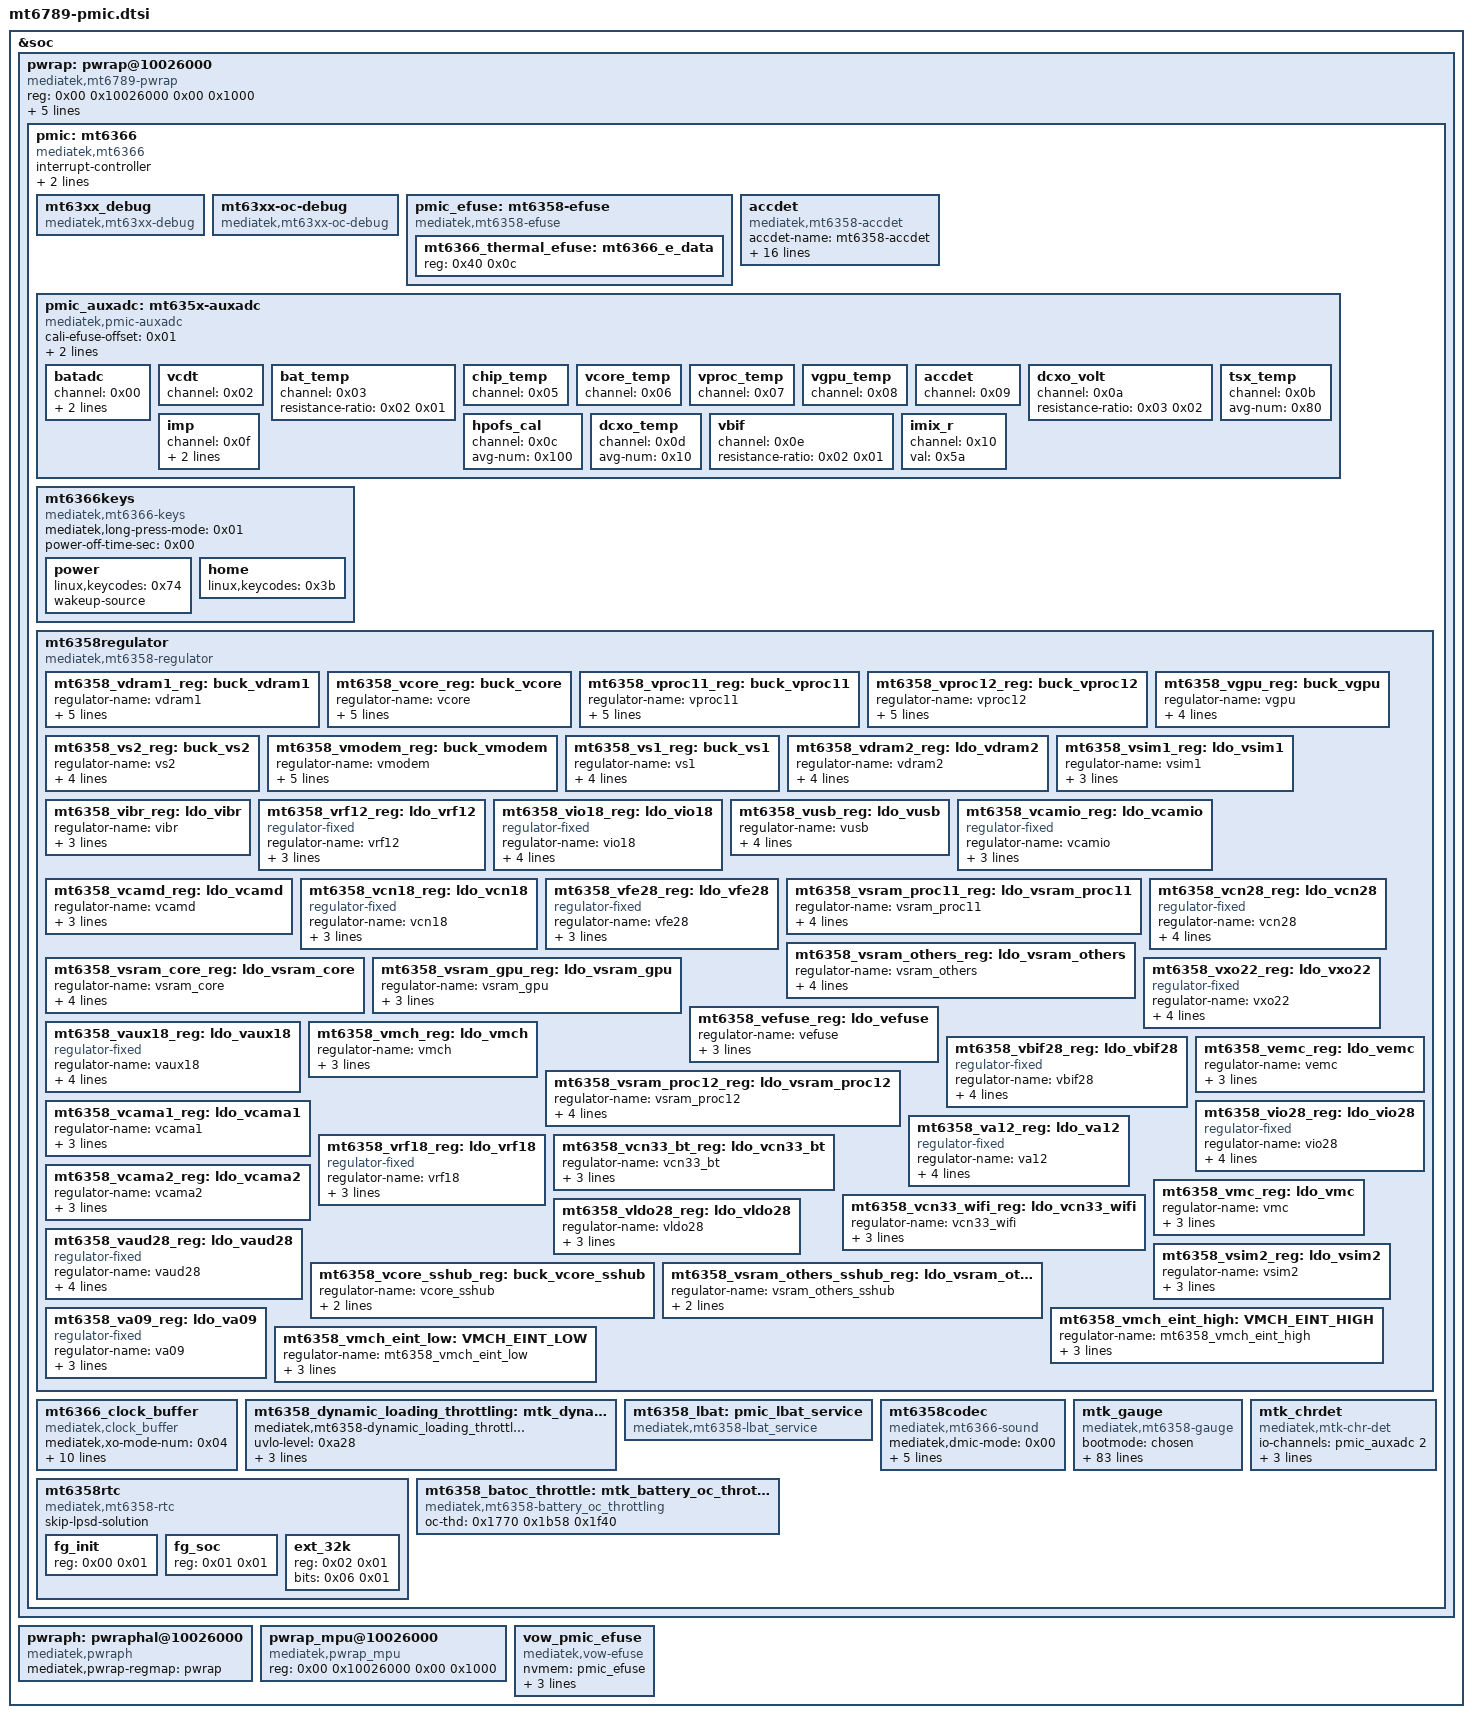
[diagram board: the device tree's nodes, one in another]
// SPDX-License-Identifier: (GPL-2.0 OR MIT)
/* MT6789 pmic blocks -- split out of the SoC node, one subsystem per file. */

&soc {
	pwrap: pwrap@10026000 {
		compatible = "mediatek,mt6789-pwrap";
		reg = <0x00 0x10026000 0x00 0x1000>;
		reg-names = "pwrap";
		interrupts = <GIC_SPI 252 IRQ_TYPE_LEVEL_HIGH 0>;
		clocks = <&infracfg_ao_clk CLK_IFRAO_PMIC_AP &infracfg_ao_clk CLK_IFRAO_PMIC_TMR &topckgen_clk CLK_TOP_PWRAP_ULPOSC_SEL &topckgen_clk CLK_TOP_OSC_D10>;
		clock-names = "spi", "wrap", "ulposc", "ulposc_osc";

		pmic: mt6366 {
			compatible = "mediatek,mt6366";
			interrupt-controller;
			#interrupt-cells = <0x02>;
			interrupt-parent = <&pio>;
			interrupts = <0x89 0x04 0x89 0x00>;

			mt63xx_debug {
				compatible = "mediatek,mt63xx-debug";
			};

			mt63xx-oc-debug {
				compatible = "mediatek,mt63xx-oc-debug";
			};

			pmic_efuse: mt6358-efuse {
				compatible = "mediatek,mt6358-efuse";
				#address-cells = <0x01>;
				#size-cells = <0x01>;

				mt6366_thermal_efuse: mt6366_e_data {
					reg = <0x40 0x0c>;
				};
			};

			accdet: accdet {
				compatible = "mediatek,mt6358-accdet";
				accdet-name = "mt6358-accdet";
				accdet-mic-vol = <0x06>;
				headset-mode-setting = <0x500 0x500 0x01 0x1f0 0x800 0x800 0x20 0x44 0x00 0x00 0x0e 0x00 0x00 0x00 0x00 0x00>;
				accdet-plugout-debounce = <0x01>;
				accdet-mic-mode = <0x01>;
				headset-eint-level-pol = <0x08>;
				headset-three-key-threshold = <0x00 0x50 0xdc 0x190>;
				headset-three-key-threshold-CDD = <0x00 0x79 0xc0 0x258>;
				headset-four-key-threshold = <0x00 0x3a 0x79 0xc0 0x190>;
				io-channels = <&pmic_auxadc 9>;
				io-channel-names = "pmic_accdet";
				nvmem = <&pmic_efuse>;
				nvmem-names = "mt63xx-accdet-efuse";
				mediatek,accdet-pmic = <0x66>;
				status = "okay";
			};

			pmic_auxadc: mt635x-auxadc {
				compatible = "mediatek,pmic-auxadc", "mediatek,mt6358-auxadc";
				#io-channel-cells = <0x01>;
				cali-efuse-offset = <0x01>;
				nvmem = <&pmic_efuse>;
				nvmem-names = "auxadc_efuse_dev";

				batadc {
					channel = <0x00>;
					resistance-ratio = <0x03 0x01>;
					avg-num = <0x80>;
				};

				vcdt {
					channel = <0x02>;
				};

				bat_temp {
					channel = <0x03>;
					resistance-ratio = <0x02 0x01>;
				};

				chip_temp {
					channel = <0x05>;
				};

				vcore_temp {
					channel = <0x06>;
				};

				vproc_temp {
					channel = <0x07>;
				};

				vgpu_temp {
					channel = <0x08>;
				};

				accdet {
					channel = <0x09>;
				};

				dcxo_volt {
					channel = <0x0a>;
					resistance-ratio = <0x03 0x02>;
				};

				tsx_temp {
					channel = <0x0b>;
					avg-num = <0x80>;
				};

				hpofs_cal {
					channel = <0x0c>;
					avg-num = <0x100>;
				};

				dcxo_temp {
					channel = <0x0d>;
					avg-num = <0x10>;
				};

				vbif {
					channel = <0x0e>;
					resistance-ratio = <0x02 0x01>;
				};

				imp {
					channel = <0x0f>;
					resistance-ratio = <0x03 0x01>;
					avg-num = <0x80>;
				};

				imix_r {
					channel = <0x10>;
					val = <0x5a>;
				};
			};

			mt6366keys: mt6366keys {
				compatible = "mediatek,mt6366-keys";
				mediatek,long-press-mode = <0x01>;
				power-off-time-sec = <0x00>;

				power {
					linux,keycodes = <0x74>;
					wakeup-source;
				};

				home {
					linux,keycodes = <0x3b>;
				};
			};

			mt6358regulator: mt6358regulator {
				compatible = "mediatek,mt6358-regulator";

				mt6358_vdram1_reg: buck_vdram1 {
					regulator-name = "vdram1";
					regulator-min-microvolt = <0x7a120>;
					regulator-max-microvolt = <0x1fda4c>;
					regulator-enable-ramp-delay = <0x00>;
					regulator-allowed-modes = <0x00 0x01>;
					regulator-always-on;
				};

				mt6358_vcore_reg: buck_vcore {
					regulator-name = "vcore";
					regulator-min-microvolt = <0x7a120>;
					regulator-max-microvolt = <0x13bdb6>;
					regulator-enable-ramp-delay = <0xc8>;
					regulator-always-on;
					regulator-allowed-modes = <0x00 0x01>;
				};

				mt6358_vproc11_reg: buck_vproc11 {
					regulator-name = "vproc11";
					regulator-min-microvolt = <0x7a120>;
					regulator-max-microvolt = <0x13bdb6>;
					regulator-enable-ramp-delay = <0xc8>;
					regulator-always-on;
					regulator-allowed-modes = <0x00 0x01>;
				};

				mt6358_vproc12_reg: buck_vproc12 {
					regulator-name = "vproc12";
					regulator-min-microvolt = <0x7a120>;
					regulator-max-microvolt = <0x13bdb6>;
					regulator-enable-ramp-delay = <0xc8>;
					regulator-always-on;
					regulator-allowed-modes = <0x00 0x01>;
				};

				mt6358_vgpu_reg: buck_vgpu {
					regulator-name = "vgpu";
					regulator-min-microvolt = <0x7a120>;
					regulator-max-microvolt = <0x13bdb6>;
					regulator-enable-ramp-delay = <0xc8>;
					regulator-allowed-modes = <0x00 0x01>;
				};

				mt6358_vs2_reg: buck_vs2 {
					regulator-name = "vs2";
					regulator-min-microvolt = <0x7a120>;
					regulator-max-microvolt = <0x1fda4c>;
					regulator-enable-ramp-delay = <0x00>;
					regulator-always-on;
				};

				mt6358_vmodem_reg: buck_vmodem {
					regulator-name = "vmodem";
					regulator-min-microvolt = <0x7a120>;
					regulator-max-microvolt = <0x13bdb6>;
					regulator-enable-ramp-delay = <0x384>;
					regulator-always-on;
					regulator-allowed-modes = <0x00 0x01>;
				};

				mt6358_vs1_reg: buck_vs1 {
					regulator-name = "vs1";
					regulator-min-microvolt = <0xf4240>;
					regulator-max-microvolt = <0x277b6c>;
					regulator-enable-ramp-delay = <0x00>;
					regulator-always-on;
				};

				mt6358_vdram2_reg: ldo_vdram2 {
					regulator-name = "vdram2";
					regulator-min-microvolt = <0x927c0>;
					regulator-max-microvolt = <0x1b7740>;
					regulator-enable-ramp-delay = <0xce4>;
					regulator-always-on;
				};

				mt6358_vsim1_reg: ldo_vsim1 {
					regulator-name = "vsim1";
					regulator-min-microvolt = <0x00>;
					regulator-max-microvolt = <0x2f4d60>;
					regulator-enable-ramp-delay = <0x21c>;
				};

				mt6358_vibr_reg: ldo_vibr {
					regulator-name = "vibr";
					regulator-min-microvolt = <0x124f80>;
					regulator-max-microvolt = <0x325aa0>;
					regulator-enable-ramp-delay = <0x3c>;
				};

				mt6358_vrf12_reg: ldo_vrf12 {
					compatible = "regulator-fixed";
					regulator-name = "vrf12";
					regulator-min-microvolt = <0x124f80>;
					regulator-max-microvolt = <0x124f80>;
					regulator-enable-ramp-delay = <0x78>;
				};

				mt6358_vio18_reg: ldo_vio18 {
					compatible = "regulator-fixed";
					regulator-name = "vio18";
					regulator-min-microvolt = <0x1b7740>;
					regulator-max-microvolt = <0x1b7740>;
					regulator-enable-ramp-delay = <0xa8c>;
					regulator-always-on;
				};

				mt6358_vusb_reg: ldo_vusb {
					regulator-name = "vusb";
					regulator-min-microvolt = <0x2dc6c0>;
					regulator-max-microvolt = <0x2f4d60>;
					regulator-enable-ramp-delay = <0x10e>;
					regulator-always-on;
				};

				mt6358_vcamio_reg: ldo_vcamio {
					compatible = "regulator-fixed";
					regulator-name = "vcamio";
					regulator-min-microvolt = <0x1b7740>;
					regulator-max-microvolt = <0x1b7740>;
					regulator-enable-ramp-delay = <0x145>;
				};

				mt6358_vcamd_reg: ldo_vcamd {
					regulator-name = "vcamd";
					regulator-min-microvolt = <0xdbba0>;
					regulator-max-microvolt = <0x1b7740>;
					regulator-enable-ramp-delay = <0x145>;
				};

				mt6358_vcn18_reg: ldo_vcn18 {
					compatible = "regulator-fixed";
					regulator-name = "vcn18";
					regulator-min-microvolt = <0x1b7740>;
					regulator-max-microvolt = <0x1b7740>;
					regulator-enable-ramp-delay = <0x10e>;
				};

				mt6358_vfe28_reg: ldo_vfe28 {
					compatible = "regulator-fixed";
					regulator-name = "vfe28";
					regulator-min-microvolt = <0x2ab980>;
					regulator-max-microvolt = <0x2ab980>;
					regulator-enable-ramp-delay = <0x10e>;
				};

				mt6358_vsram_proc11_reg: ldo_vsram_proc11 {
					regulator-name = "vsram_proc11";
					regulator-min-microvolt = <0x7a120>;
					regulator-max-microvolt = <0x13bdb6>;
					regulator-enable-ramp-delay = <0xf0>;
					regulator-always-on;
				};

				mt6358_vcn28_reg: ldo_vcn28 {
					compatible = "regulator-fixed";
					regulator-name = "vcn28";
					regulator-min-microvolt = <0x2ab980>;
					regulator-max-microvolt = <0x2ab980>;
					regulator-enable-ramp-delay = <0x10e>;
					regulator-always-on;
				};

				mt6358_vsram_others_reg: ldo_vsram_others {
					regulator-name = "vsram_others";
					regulator-min-microvolt = <0x7a120>;
					regulator-max-microvolt = <0x13bdb6>;
					regulator-enable-ramp-delay = <0xf0>;
					regulator-always-on;
				};

				mt6358_vsram_core_reg: ldo_vsram_core {
					regulator-name = "vsram_core";
					regulator-min-microvolt = <0x7a120>;
					regulator-max-microvolt = <0x13bdb6>;
					regulator-enable-ramp-delay = <0xf0>;
					regulator-always-on;
				};

				mt6358_vsram_gpu_reg: ldo_vsram_gpu {
					regulator-name = "vsram_gpu";
					regulator-min-microvolt = <0x7a120>;
					regulator-max-microvolt = <0x13bdb6>;
					regulator-enable-ramp-delay = <0xf0>;
				};

				mt6358_vxo22_reg: ldo_vxo22 {
					compatible = "regulator-fixed";
					regulator-name = "vxo22";
					regulator-min-microvolt = <0x2191c0>;
					regulator-max-microvolt = <0x2191c0>;
					regulator-enable-ramp-delay = <0x78>;
					regulator-always-on;
				};

				mt6358_vefuse_reg: ldo_vefuse {
					regulator-name = "vefuse";
					regulator-min-microvolt = <0x19f0a0>;
					regulator-max-microvolt = <0x1cfde0>;
					regulator-enable-ramp-delay = <0x10e>;
				};

				mt6358_vaux18_reg: ldo_vaux18 {
					compatible = "regulator-fixed";
					regulator-name = "vaux18";
					regulator-min-microvolt = <0x1b7740>;
					regulator-max-microvolt = <0x1b7740>;
					regulator-enable-ramp-delay = <0x10e>;
					regulator-always-on;
				};

				mt6358_vmch_reg: ldo_vmch {
					regulator-name = "vmch";
					regulator-min-microvolt = <0x2c4020>;
					regulator-max-microvolt = <0x325aa0>;
					regulator-enable-ramp-delay = <0x3c>;
				};

				mt6358_vbif28_reg: ldo_vbif28 {
					compatible = "regulator-fixed";
					regulator-name = "vbif28";
					regulator-min-microvolt = <0x2ab980>;
					regulator-max-microvolt = <0x2ab980>;
					regulator-enable-ramp-delay = <0x10e>;
					regulator-always-on;
				};

				mt6358_vsram_proc12_reg: ldo_vsram_proc12 {
					regulator-name = "vsram_proc12";
					regulator-min-microvolt = <0x7a120>;
					regulator-max-microvolt = <0x13bdb6>;
					regulator-enable-ramp-delay = <0xf0>;
					regulator-always-on;
				};

				mt6358_vcama1_reg: ldo_vcama1 {
					regulator-name = "vcama1";
					regulator-min-microvolt = <0x1b7740>;
					regulator-max-microvolt = <0x2dc6c0>;
					regulator-enable-ramp-delay = <0x145>;
				};

				mt6358_vemc_reg: ldo_vemc {
					regulator-name = "vemc";
					regulator-min-microvolt = <0x2c4020>;
					regulator-max-microvolt = <0x325aa0>;
					regulator-enable-ramp-delay = <0x3c>;
				};

				mt6358_vio28_reg: ldo_vio28 {
					compatible = "regulator-fixed";
					regulator-name = "vio28";
					regulator-min-microvolt = <0x2ab980>;
					regulator-max-microvolt = <0x2ab980>;
					regulator-enable-ramp-delay = <0x10e>;
					regulator-always-on;
				};

				mt6358_va12_reg: ldo_va12 {
					compatible = "regulator-fixed";
					regulator-name = "va12";
					regulator-min-microvolt = <0x124f80>;
					regulator-max-microvolt = <0x124f80>;
					regulator-enable-ramp-delay = <0x10e>;
					regulator-always-on;
				};

				mt6358_vrf18_reg: ldo_vrf18 {
					compatible = "regulator-fixed";
					regulator-name = "vrf18";
					regulator-min-microvolt = <0x1b7740>;
					regulator-max-microvolt = <0x1b7740>;
					regulator-enable-ramp-delay = <0x78>;
				};

				mt6358_vcn33_bt_reg: ldo_vcn33_bt {
					regulator-name = "vcn33_bt";
					regulator-min-microvolt = <0x325aa0>;
					regulator-max-microvolt = <0x3567e0>;
					regulator-enable-ramp-delay = <0x10e>;
				};

				mt6358_vcn33_wifi_reg: ldo_vcn33_wifi {
					regulator-name = "vcn33_wifi";
					regulator-min-microvolt = <0x325aa0>;
					regulator-max-microvolt = <0x3567e0>;
					regulator-enable-ramp-delay = <0x10e>;
				};

				mt6358_vcama2_reg: ldo_vcama2 {
					regulator-name = "vcama2";
					regulator-min-microvolt = <0x1b7740>;
					regulator-max-microvolt = <0x2dc6c0>;
					regulator-enable-ramp-delay = <0x145>;
				};

				mt6358_vmc_reg: ldo_vmc {
					regulator-name = "vmc";
					regulator-min-microvolt = <0x1b7740>;
					regulator-max-microvolt = <0x325aa0>;
					regulator-enable-ramp-delay = <0x3c>;
				};

				mt6358_vldo28_reg: ldo_vldo28 {
					regulator-name = "vldo28";
					regulator-min-microvolt = <0x2ab980>;
					regulator-max-microvolt = <0x2dc6c0>;
					regulator-enable-ramp-delay = <0x10e>;
				};

				mt6358_vaud28_reg: ldo_vaud28 {
					compatible = "regulator-fixed";
					regulator-name = "vaud28";
					regulator-min-microvolt = <0x2ab980>;
					regulator-max-microvolt = <0x2ab980>;
					regulator-enable-ramp-delay = <0x10e>;
					regulator-always-on;
				};

				mt6358_vsim2_reg: ldo_vsim2 {
					regulator-name = "vsim2";
					regulator-min-microvolt = <0x00>;
					regulator-max-microvolt = <0x2f4d60>;
					regulator-enable-ramp-delay = <0x21c>;
				};

				mt6358_vcore_sshub_reg: buck_vcore_sshub {
					regulator-name = "vcore_sshub";
					regulator-min-microvolt = <0x7a120>;
					regulator-max-microvolt = <0x13bdb6>;
				};

				mt6358_vsram_others_sshub_reg: ldo_vsram_others_sshub {
					regulator-name = "vsram_others_sshub";
					regulator-min-microvolt = <0x7a120>;
					regulator-max-microvolt = <0x13bdb6>;
				};

				mt6358_va09_reg: ldo_va09 {
					regulator-name = "va09";
					compatible = "regulator-fixed";
					regulator-min-microvolt = <0xdbba0>;
					regulator-max-microvolt = <0xdbba0>;
					regulator-enable-ramp-delay = <0x108>;
				};

				mt6358_vmch_eint_high: VMCH_EINT_HIGH {
					regulator-name = "mt6358_vmch_eint_high";
					regulator-min-microvolt = <0x2c4020>;
					regulator-max-microvolt = <0x325aa0>;
					regulator-enable-ramp-delay = <0x3c>;
				};

				mt6358_vmch_eint_low: VMCH_EINT_LOW {
					regulator-name = "mt6358_vmch_eint_low";
					regulator-min-microvolt = <0x2c4020>;
					regulator-max-microvolt = <0x325aa0>;
					regulator-enable-ramp-delay = <0x3c>;
				};
			};

			mt6366_clock_buffer: mt6366_clock_buffer {
				compatible = "mediatek,clock_buffer";
				mediatek,xo-mode-num = <0x04>;
				mediatek,xo-buf-support = <0x01 0x01 0x01 0x01 0x00 0x00 0x01>;
				mediatek,xo-buf-allow-control = <0x00 0x01 0x01 0x01 0x00 0x00 0x01>;
				mediatek,xo-buf-name = "XO_SOC", "XO_WCN", "XO_NFC", "XO_CEL", "RSV1", "RSV2", "XO_EXT";
				mediatek,dcxo-drv-curr-support;
				mediatek,clkbuf-pmic-central-base;
				mediatek,enable;
				clkbuf_ctl = <&clock_buffer_ctrl>;
			};

			mt6358_dynamic_loading_throttling: mtk_dynamic_loading_throttling {
				compatible = "mediatek,mt6358-dynamic_loading_throttling";
				uvlo-level = <0xa28>;
				io-channels = <&pmic_auxadc 15 &pmic_auxadc 16 &pmic_auxadc 0>;
				io-channel-names = "pmic_ptim", "pmic_imix_r", "pmic_batadc";
				bootmode = <&chosen>;
			};

			mt6358_lbat: pmic_lbat_service {
				compatible = "mediatek,mt6358-lbat_service";
			};

			mt6358codec: mt6358codec {
				compatible = "mediatek,mt6366-sound";
				mediatek,dmic-mode = <0x00>;
				mediatek,mic-type = <0x02>;
				io-channels = <&pmic_auxadc 12>;
				io-channel-names = "pmic_hpofs_cal";
				nvmem = <&pmic_efuse>;
				nvmem-names = "pmic-hp-efuse";
				reg_vaud28-supply = <&mt6358_vaud28_reg>;
			};

			mt6358rtc: mt6358rtc {
				compatible = "mediatek,mt6358-rtc";
				skip-lpsd-solution;
				#address-cells = <0x01>;
				#size-cells = <0x01>;

				fg_init: fg_init {
					reg = <0x00 0x01>;
				};

				fg_soc: fg_soc {
					reg = <0x01 0x01>;
				};

				ext_32k: ext_32k {
					reg = <0x02 0x01>;
					bits = <0x06 0x01>;
				};
			};

			mtk_gauge: mtk_gauge {
				compatible = "mediatek,mt6358-gauge";
				bootmode = <&chosen>;
				io-channels = <&pmic_auxadc 3 &pmic_auxadc 0 &pmic_auxadc 14 &pmic_auxadc 15 &pmic_auxadc 16>;
				io-channel-names = "pmic_battery_temp", "pmic_battery_voltage", "pmic_bif_voltage", "pmic_ptim_voltage", "pmic_ptim_r";
				nvmem-cells = <&fg_init &fg_soc>;
				nvmem-cell-names = "initialization", "state-of-charge";
				charger = <&eta6965_chg>;
				DIFFERENCE_FULLOCV_ITH = <0xc8>;
				SHUTDOWN_1_TIME = <0x05>;
				KEEP_100_PERCENT = <0x01>;
				R_FG_VALUE = <0x0a>;
				EMBEDDED_SEL = <0x01>;
				PMIC_SHUTDOWN_CURRENT = <0x14>;
				FG_METER_RESISTANCE = <0x46>;
				CAR_TUNE_VALUE = <0x65>;
				PMIC_MIN_VOL = <0x82dc>;
				POWERON_SYSTEM_IBOOT = <0x1f4>;
				SHUTDOWN_GAUGE0_VOLTAGE = <0x84d0>;
				TEMPERATURE_T0 = <0x32>;
				TEMPERATURE_T1 = <0x19>;
				TEMPERATURE_T2 = <0x0a>;
				TEMPERATURE_T3 = <0x00>;
				TEMPERATURE_T4 = <0xfffffff9>;
				TEMPERATURE_T5 = <0xfffffff6>;
				g_FG_PSEUDO100_T0 = <0x64>;
				g_FG_PSEUDO100_T1 = <0x64>;
				g_FG_PSEUDO100_T2 = <0x64>;
				g_FG_PSEUDO100_T3 = <0x64>;
				g_FG_PSEUDO100_T4 = <0x64>;
				Q_MAX_SYS_VOLTAGE_BAT0 = <0xd16>;
				Q_MAX_SYS_VOLTAGE_BAT1 = <0xd16>;
				Q_MAX_SYS_VOLTAGE_BAT2 = <0xd16>;
				Q_MAX_SYS_VOLTAGE_BAT3 = <0xd16>;
				COM_FG_METER_RESISTANCE = <0x64>;
				COM_R_FG_VALUE = <0x00>;
				enable_tmp_intr_suspend = <0x00>;
				ACTIVE_TABLE = <0x06>;
				MULTI_TEMP_GAUGE0 = <0x01>;
				RBAT_PULL_UP_VOLT = <0xaf0>;
				battery0_profile_t0_num = <0x64>;
				battery0_profile_t0_col = <0x03>;
				battery0_profile_t0 = <0x00 0xacd9 0x47e 0xca 0xac5f 0x238 0x194 0xabfb 0x25a 0x25e 0xab7a 0x23f 0x328 0xab0f 0x242 0x3f2 0xaaa4 0x247 0x4bc 0xaa2b 0x230 0x586 0xa9c7 0x27a 0x650 0xa956 0x24d 0x71a 0xa8f1 0x278 0x7e4 0xa86b 0x243 0x8ae 0xa7f4 0x261 0x978 0xa76a 0x255 0xa43 0xa6f8 0x255 0xb0d 0xa67a 0x255 0xbd7 0xa600 0x264 0xca1 0xa57e 0x256 0xd6b 0xa4f9 0x222 0xe35 0xa484 0x265 0xeff 0xa407 0x266 0xfc9 0xa38e 0x26e 0x1093 0xa310 0x26e 0x115d 0xa296 0x26f 0x1227 0xa21e 0x279 0x12f1 0xa1a6 0x27c 0x13bb 0xa131 0x282 0x1485 0xa0bb 0x287 0x154f 0xa047 0x288 0x1619 0x9fd7 0x292 0x16e3 0x9f66 0x29b 0x17ad 0x9ef9 0x29f 0x1877 0x9e8f 0x2af 0x1941 0x9e32 0x2b6 0x1a0b 0x9dff 0x2b9 0x1ad5 0x9dbc 0x2c3 0x1b9f 0x9d56 0x2d6 0x1c69 0x9d07 0x2e2 0x1d33 0x9ce6 0x2e4 0x1dfe 0x9cc5 0x2e5 0x1ec8 0x9c8b 0x2ef 0x1f92 0x9c26 0x303 0x205c 0x9bbd 0x30f 0x2126 0x9b4b 0x30d 0x21f0 0x9ac4 0x2e9 0x22ba 0x9a33 0x2a7 0x2384 0x99aa 0x27b 0x244e 0x9939 0x267 0x2518 0x98db 0x258 0x25e2 0x9886 0x254 0x26ac 0x9837 0x24f 0x2776 0x97ed 0x24f 0x2840 0x97a7 0x24d 0x290a 0x9764 0x24a 0x29d4 0x9724 0x24d 0x2a9e 0x96f1 0x24c 0x2b68 0x96c6 0x24d 0x2c32 0x9676 0x257 0x2cfc 0x9640 0x25a 0x2dc6 0x960a 0x25e 0x2e90 0x95d9 0x262 0x2f5a 0x95a8 0x26c 0x3024 0x9578 0x273 0x30ef 0x954d 0x27a 0x31b9 0x9521 0x282 0x3283 0x94f7 0x28a 0x334d 0x94d2 0x296 0x3417 0x94aa 0x29f 0x34e1 0x9483 0x2a7 0x35ab 0x945f 0x2b3 0x3675 0x9431 0x2ae 0x373f 0x93fb 0x2a2 0x3809 0x93b0 0x277 0x38d3 0x9357 0x252 0x399d 0x9317 0x264 0x3a67 0x92e6 0x26b 0x3b31 0x92ad 0x264 0x3bfb 0x927e 0x279 0x3cc5 0x9248 0x25e 0x3d8f 0x9212 0x25f 0x3e59 0x91f1 0x283 0x3f23 0x91c2 0x26f 0x3fed 0x9190 0x27f 0x40b7 0x9159 0x281 0x4181 0x910c 0x263 0x424b 0x90d5 0x285 0x4315 0x9091 0x26d 0x43df 0x9045 0x276 0x44aa 0x9003 0x25a 0x4574 0x8fd6 0x237 0x463e 0x8fd0 0x275 0x4708 0x8fc7 0x28f 0x47d2 0x8fb1 0x2b3 0x489c 0x8fa7 0x312 0x4966 0x8f5b 0x2f4 0x4a30 0x8e7a 0x2b4 0x4afa 0x8ce6 0x2ce 0x4bc4 0x8a92 0x29e 0x4c8e 0x878c 0x2da 0x4d58 0x8771 0x2dd 0x4e22 0x8771 0x2dd>;
				battery0_profile_t1_num = <0x64>;
				battery0_profile_t1_col = <0x03>;
				battery0_profile_t1 = <0x00 0xad20 0x47e 0xca 0xad00 0x430 0x194 0xac56 0x33c 0x25e 0xac05 0x3cd 0x328 0xab97 0x385 0x3f2 0xab45 0x39d 0x4bc 0xaaea 0x3a0 0x586 0xaa84 0x3cf 0x650 0xaa15 0x3cd 0x71a 0xa9a7 0x3bb 0x7e4 0xa941 0x3e3 0x8ae 0xa8d1 0x3b3 0x978 0xa856 0x39d 0xa43 0xa7d6 0x3a0 0xb0d 0xa765 0x3b0 0xbd7 0xa6e2 0x37d 0xca1 0xa65f 0x35a 0xd6b 0xa5e8 0x384 0xe35 0xa56b 0x380 0xeff 0xa4ea 0x37d 0xfc9 0xa472 0x3c6 0x1093 0xa3f8 0x3a2 0x115d 0xa37e 0x3bb 0x1227 0xa304 0x3c4 0x12f1 0xa281 0x398 0x13bb 0xa21a 0x3c7 0x1485 0xa1dd 0x458 0x154f 0xa126 0x3b1 0x1619 0xa0b8 0x3da 0x16e3 0xa03d 0x3d3 0x17ad 0x9fe3 0x435 0x1877 0x9f80 0x459 0x1941 0x9eff 0x401 0x1a0b 0x9ec7 0x401 0x1ad5 0x9e7e 0x3f9 0x1b9f 0x9e24 0x419 0x1c69 0x9dee 0x472 0x1d33 0x9db5 0x451 0x1dfe 0x9d7c 0x42f 0x1ec8 0x9d32 0x42d 0x1f92 0x9cc6 0x442 0x205c 0x9c50 0x429 0x2126 0x9bd1 0x3f1 0x21f0 0x9b42 0x3ac 0x22ba 0x9ab4 0x371 0x2384 0x9a2e 0x350 0x244e 0x99ca 0x38d 0x2518 0x9962 0x35b 0x25e2 0x98fa 0x312 0x26ac 0x98a8 0x345 0x2776 0x985d 0x339 0x2840 0x9817 0x346 0x290a 0x97d1 0x36b 0x29d4 0x978a 0x35e 0x2a9e 0x9752 0x35b 0x2b68 0x9727 0x363 0x2c32 0x96ce 0x307 0x2cfc 0x9697 0x307 0x2dc6 0x965f 0x2f8 0x2e90 0x962a 0x2e0 0x2f5a 0x95f5 0x303 0x3024 0x95c9 0x2f2 0x30ef 0x95a2 0x312 0x31b9 0x9579 0x349 0x3283 0x954a 0x342 0x334d 0x9524 0x36a 0x3417 0x94fe 0x373 0x34e1 0x94d0 0x36b 0x35ab 0x94a5 0x349 0x3675 0x9483 0x339 0x373f 0x9465 0x34a 0x3809 0x9439 0x386 0x38d3 0x9406 0x356 0x399d 0x93cd 0x327 0x3a67 0x9397 0x30e 0x3b31 0x936c 0x364 0x3bfb 0x9335 0x326 0x3cc5 0x9300 0x31a 0x3d8f 0x92d5 0x30d 0x3e59 0x92a5 0x307 0x3f23 0x9282 0x343 0x3fed 0x9264 0x33e 0x40b7 0x923d 0x34d 0x4181 0x9215 0x367 0x424b 0x91d1 0x355 0x4315 0x918d 0x33d 0x43df 0x914f 0x324 0x44aa 0x911b 0x34b 0x4574 0x90e8 0x37e 0x463e 0x9087 0x2fb 0x4708 0x9063 0x331 0x47d2 0x904e 0x339 0x489c 0x9043 0x367 0x4966 0x9025 0x36b 0x4a30 0x9011 0x382 0x4afa 0x8ffd 0x429 0x4bc4 0x8f64 0x3b5 0x4c8e 0x8dc2 0x28d 0x4d58 0x8af5 0x358 0x4e22 0x85ac 0x401>;
				battery0_profile_t2_num = <0x64>;
				battery0_profile_t2_col = <0x03>;
				battery0_profile_t2 = <0x00 0xad20 0x47e 0xca 0xad00 0x430 0x194 0xac56 0x33c 0x25e 0xac05 0x3cd 0x328 0xab97 0x385 0x3f2 0xab45 0x39d 0x4bc 0xaaea 0x3a0 0x586 0xaa84 0x3cf 0x650 0xaa15 0x3cd 0x71a 0xa9a7 0x3bb 0x7e4 0xa941 0x3e3 0x8ae 0xa8d1 0x3b3 0x978 0xa856 0x39d 0xa43 0xa7d6 0x3a0 0xb0d 0xa765 0x3b0 0xbd7 0xa6e2 0x37d 0xca1 0xa65f 0x35a 0xd6b 0xa5e8 0x384 0xe35 0xa56b 0x380 0xeff 0xa4ea 0x37d 0xfc9 0xa472 0x3c6 0x1093 0xa3f8 0x3a2 0x115d 0xa37e 0x3bb 0x1227 0xa304 0x3c4 0x12f1 0xa281 0x398 0x13bb 0xa21a 0x3c7 0x1485 0xa1dd 0x458 0x154f 0xa126 0x3b1 0x1619 0xa0b8 0x3da 0x16e3 0xa03d 0x3d3 0x17ad 0x9fe3 0x435 0x1877 0x9f80 0x459 0x1941 0x9eff 0x401 0x1a0b 0x9ec7 0x401 0x1ad5 0x9e7e 0x3f9 0x1b9f 0x9e24 0x419 0x1c69 0x9dee 0x472 0x1d33 0x9db5 0x451 0x1dfe 0x9d7c 0x42f 0x1ec8 0x9d32 0x42d 0x1f92 0x9cc6 0x442 0x205c 0x9c50 0x429 0x2126 0x9bd1 0x3f1 0x21f0 0x9b42 0x3ac 0x22ba 0x9ab4 0x371 0x2384 0x9a2e 0x350 0x244e 0x99ca 0x38d 0x2518 0x9962 0x35b 0x25e2 0x98fa 0x312 0x26ac 0x98a8 0x345 0x2776 0x985d 0x339 0x2840 0x9817 0x346 0x290a 0x97d1 0x36b 0x29d4 0x978a 0x35e 0x2a9e 0x9752 0x35b 0x2b68 0x9727 0x363 0x2c32 0x96ce 0x307 0x2cfc 0x9697 0x307 0x2dc6 0x965f 0x2f8 0x2e90 0x962a 0x2e0 0x2f5a 0x95f5 0x303 0x3024 0x95c9 0x2f2 0x30ef 0x95a2 0x312 0x31b9 0x9579 0x349 0x3283 0x954a 0x342 0x334d 0x9524 0x36a 0x3417 0x94fe 0x373 0x34e1 0x94d0 0x36b 0x35ab 0x94a5 0x349 0x3675 0x9483 0x339 0x373f 0x9465 0x34a 0x3809 0x9439 0x386 0x38d3 0x9406 0x356 0x399d 0x93cd 0x327 0x3a67 0x9397 0x30e 0x3b31 0x936c 0x364 0x3bfb 0x9335 0x326 0x3cc5 0x9300 0x31a 0x3d8f 0x92d5 0x30d 0x3e59 0x92a5 0x307 0x3f23 0x9282 0x343 0x3fed 0x9264 0x33e 0x40b7 0x923d 0x34d 0x4181 0x9215 0x367 0x424b 0x91d1 0x355 0x4315 0x918d 0x33d 0x43df 0x914f 0x324 0x44aa 0x911b 0x34b 0x4574 0x90e8 0x37e 0x463e 0x9087 0x2fb 0x4708 0x9063 0x331 0x47d2 0x904e 0x339 0x489c 0x9043 0x367 0x4966 0x9025 0x36b 0x4a30 0x9011 0x382 0x4afa 0x8ffd 0x429 0x4bc4 0x8f64 0x3b5 0x4c8e 0x8dc2 0x28d 0x4d58 0x8af5 0x358 0x4e22 0x85ac 0x401>;
				battery0_profile_t3_num = <0x64>;
				battery0_profile_t3_col = <0x03>;
				battery0_profile_t3 = <0x00 0xad10 0x47e 0xca 0xac84 0x113d 0x194 0xac0e 0x1080 0x25e 0xaba0 0x1057 0x328 0xab39 0x1074 0x3f2 0xaacf 0x1024 0x4bc 0xaa6a 0x104b 0x586 0xaa04 0xfe3 0x650 0xa9a3 0xfdd 0x71a 0xa92e 0xfaf 0x7e4 0xa8c1 0xf92 0x8ae 0xa859 0xf85 0x978 0xa7d9 0xf75 0xa43 0xa76d 0xf6a 0xb0d 0xa6f6 0xf4a 0xbd7 0xa676 0xf18 0xca1 0xa5f1 0xee7 0xd6b 0xa57d 0xee0 0xe35 0xa504 0xec9 0xeff 0xa497 0xed7 0xfc9 0xa44c 0xf40 0x1093 0xa3be 0xf0d 0x115d 0xa321 0xe85 0x1227 0xa2a9 0xe5e 0x12f1 0xa233 0xe06 0x13bb 0xa1c5 0xe63 0x1485 0xa162 0xe88 0x154f 0xa0ce 0xe35 0x1619 0xa058 0xe05 0x16e3 0x9fe5 0xde6 0x17ad 0x9f78 0xe07 0x1877 0x9f00 0xdbd 0x1941 0x9e9f 0xe24 0x1a0b 0x9e62 0xe1b 0x1ad5 0x9e10 0xe0c 0x1b9f 0x9d91 0xdeb 0x1c69 0x9d2e 0xdcb 0x1d33 0x9d02 0xdbf 0x1dfe 0x9cd6 0xdb3 0x1ec8 0x9c8a 0xd84 0x1f92 0x9c08 0xd32 0x205c 0x9b87 0xcfe 0x2126 0x9b0e 0xcc8 0x21f0 0x9a99 0xc9a 0x22ba 0x9a2a 0xc71 0x2384 0x99c4 0xc4e 0x244e 0x9967 0xc39 0x2518 0x990d 0xc25 0x25e2 0x98b6 0xc16 0x26ac 0x9863 0xc00 0x2776 0x9814 0xbed 0x2840 0x97cb 0xbe7 0x290a 0x9784 0xbe9 0x29d4 0x9740 0xbf8 0x2a9e 0x9709 0xbfb 0x2b68 0x96dc 0xbfd 0x2c32 0x9684 0xc07 0x2cfc 0x964c 0xc11 0x2dc6 0x9615 0xc13 0x2e90 0x95e1 0xc17 0x2f5a 0x95ad 0xc21 0x3024 0x957c 0xc2d 0x30ef 0x954d 0xc3c 0x31b9 0x9520 0xc4f 0x3283 0x94f3 0xc5e 0x334d 0x94c9 0xc6a 0x3417 0x949f 0xc79 0x34e1 0x9478 0xc89 0x35ab 0x9453 0xc97 0x3675 0x942e 0xca1 0x373f 0x9409 0xca6 0x3809 0x93e8 0xcb1 0x38d3 0x93ca 0xcc1 0x399d 0x93ae 0xcde 0x3a67 0x9393 0xcfb 0x3b31 0x9376 0xd21 0x3bfb 0x9359 0xd4c 0x3cc5 0x933b 0xd7f 0x3d8f 0x931b 0xdbf 0x3e59 0x92f8 0xe08 0x3f23 0x92d4 0xe55 0x3fed 0x92ab 0xeb0 0x40b7 0x927d 0xf0d 0x4181 0x9249 0xf6c 0x424b 0x920e 0xfd9 0x4315 0x91d1 0x104e 0x43df 0x9190 0x10cf 0x44aa 0x914c 0x1155 0x4574 0x9100 0x11e4 0x463e 0x90b3 0x127c 0x4708 0x9075 0x1324 0x47d2 0x905c 0x141e 0x489c 0x9027 0x14f9 0x4966 0x9006 0x1612 0x4a30 0x8fdf 0x1764 0x4afa 0x8f9b 0x181f 0x4bc4 0x8f17 0x1ab3 0x4c8e 0x8f17 0x1ab3 0x4d58 0x8f17 0x1ab3 0x4e22 0x8f17 0x1ab3>;
				battery0_profile_t4_num = <0x64>;
				battery0_profile_t4_col = <0x03>;
				battery0_profile_t4 = <0x00 0xacf3 0x47e 0xca 0xac65 0x1a89 0x194 0xabcd 0x1aa0 0x25e 0xab7b 0x1d30 0x328 0xab38 0x1cfe 0x3f2 0xaace 0x212d 0x4bc 0xaa73 0x22d9 0x586 0xa9fd 0x2275 0x650 0xa997 0x228a 0x71a 0xa96a 0x2413 0x7e4 0xa90f 0x2428 0x8ae 0xa855 0x2329 0x978 0xa7dd 0x22dc 0xa43 0xa75c 0x2279 0xb0d 0xa6f0 0x224e 0xbd7 0xa679 0x21ec 0xca1 0xa5f2 0x21bd 0xd6b 0xa583 0x210f 0xe35 0xa543 0x1f06 0xeff 0xa49b 0x1d86 0xfc9 0xa3d4 0x1d84 0x1093 0xa321 0x1d57 0x115d 0xa298 0x1d3f 0x1227 0xa23d 0x1d9c 0x12f1 0xa154 0x1c87 0x13bb 0xa0aa 0x1be3 0x1485 0x9fd7 0x1ad9 0x154f 0x9f52 0x1ab5 0x1619 0x9ec9 0x1a74 0x16e3 0x9e41 0x1a17 0x17ad 0x9db9 0x19ac 0x1877 0x9d30 0x194f 0x1941 0x9cbc 0x1902 0x1a0b 0x9c79 0x18d9 0x1ad5 0x9c21 0x18a9 0x1b9f 0x9ba6 0x16e5 0x1c69 0x9b4e 0x1462 0x1d33 0x9b24 0x15eb 0x1dfe 0x9afb 0x1773 0x1ec8 0x9aba 0x1868 0x1f92 0x9a50 0x1850 0x205c 0x99e7 0x181b 0x2126 0x9989 0x1801 0x21f0 0x992e 0x17f2 0x22ba 0x98d4 0x17de 0x2384 0x987e 0x17cd 0x244e 0x981b 0x1797 0x2518 0x97c7 0x1784 0x25e2 0x978e 0x17bd 0x26ac 0x9746 0x17d4 0x2776 0x96f6 0x17c2 0x2840 0x96b1 0x17d0 0x290a 0x967b 0x180c 0x29d4 0x963b 0x1826 0x2a9e 0x9607 0x183a 0x2b68 0x95dd 0x1851 0x2c32 0x9588 0x187c 0x2cfc 0x9553 0x18a5 0x2dc6 0x9523 0x18f2 0x2e90 0x94f0 0x1931 0x2f5a 0x94bc 0x1956 0x3024 0x949a 0x199e 0x30ef 0x947c 0x19d7 0x31b9 0x9457 0x1a03 0x3283 0x9437 0x1a53 0x334d 0x941b 0x1acc 0x3417 0x9400 0x1b58 0x34e1 0x93e6 0x1bf3 0x35ab 0x93ca 0x1cad 0x3675 0x93ae 0x1d80 0x373f 0x9391 0x1e69 0x3809 0x9372 0x1f55 0x38d3 0x9351 0x2057 0x399d 0x932e 0x216e 0x3a67 0x9309 0x21dc 0x3b31 0x92e0 0x2307 0x3bfb 0x92d8 0x2355 0x3cc5 0x92d8 0x2355 0x3d8f 0x92d8 0x2355 0x3e59 0x92d8 0x2355 0x3f23 0x92d8 0x2355 0x3fed 0x92d8 0x2355 0x40b7 0x92d8 0x2355 0x4181 0x92d8 0x2355 0x424b 0x92d8 0x2355 0x4315 0x92d8 0x2355 0x43df 0x92d8 0x2355 0x44aa 0x92d8 0x2355 0x4574 0x92d8 0x2355 0x463e 0x92d8 0x2355 0x4708 0x92d8 0x2355 0x47d2 0x92d8 0x2355 0x489c 0x92d8 0x2355 0x4966 0x92d8 0x2355 0x4a30 0x92d8 0x2355 0x4afa 0x92d8 0x2355 0x4bc4 0x92d8 0x2355 0x4c8e 0x92d8 0x2355 0x4d58 0x92d8 0x2355 0x4e22 0x92d8 0x2355>;
				battery0_profile_t5_num = <0x64>;
				battery0_profile_t5_col = <0x03>;
				battery0_profile_t5 = <0x00 0xacf3 0x47e 0xca 0xac65 0x1a89 0x194 0xabcd 0x1aa0 0x25e 0xab7b 0x1d30 0x328 0xab38 0x1cfe 0x3f2 0xaace 0x212d 0x4bc 0xaa73 0x22d9 0x586 0xa9fd 0x2275 0x650 0xa997 0x228a 0x71a 0xa96a 0x2413 0x7e4 0xa90f 0x2428 0x8ae 0xa855 0x2329 0x978 0xa7dd 0x22dc 0xa43 0xa75c 0x2279 0xb0d 0xa6f0 0x224e 0xbd7 0xa679 0x21ec 0xca1 0xa5f2 0x21bd 0xd6b 0xa583 0x210f 0xe35 0xa543 0x1f06 0xeff 0xa49b 0x1d86 0xfc9 0xa3d4 0x1d84 0x1093 0xa321 0x1d57 0x115d 0xa298 0x1d3f 0x1227 0xa23d 0x1d9c 0x12f1 0xa154 0x1c87 0x13bb 0xa0aa 0x1be3 0x1485 0x9fd7 0x1ad9 0x154f 0x9f52 0x1ab5 0x1619 0x9ec9 0x1a74 0x16e3 0x9e41 0x1a17 0x17ad 0x9db9 0x19ac 0x1877 0x9d30 0x194f 0x1941 0x9cbc 0x1902 0x1a0b 0x9c79 0x18d9 0x1ad5 0x9c21 0x18a9 0x1b9f 0x9ba6 0x16e5 0x1c69 0x9b4e 0x1462 0x1d33 0x9b24 0x15eb 0x1dfe 0x9afb 0x1773 0x1ec8 0x9aba 0x1868 0x1f92 0x9a50 0x1850 0x205c 0x99e7 0x181b 0x2126 0x9989 0x1801 0x21f0 0x992e 0x17f2 0x22ba 0x98d4 0x17de 0x2384 0x987e 0x17cd 0x244e 0x981b 0x1797 0x2518 0x97c7 0x1784 0x25e2 0x978e 0x17bd 0x26ac 0x9746 0x17d4 0x2776 0x96f6 0x17c2 0x2840 0x96b1 0x17d0 0x290a 0x967b 0x180c 0x29d4 0x963b 0x1826 0x2a9e 0x9607 0x183a 0x2b68 0x95dd 0x1851 0x2c32 0x9588 0x187c 0x2cfc 0x9553 0x18a5 0x2dc6 0x9523 0x18f2 0x2e90 0x94f0 0x1931 0x2f5a 0x94bc 0x1956 0x3024 0x949a 0x199e 0x30ef 0x947c 0x19d7 0x31b9 0x9457 0x1a03 0x3283 0x9437 0x1a53 0x334d 0x941b 0x1acc 0x3417 0x9400 0x1b58 0x34e1 0x93e6 0x1bf3 0x35ab 0x93ca 0x1cad 0x3675 0x93ae 0x1d80 0x373f 0x9391 0x1e69 0x3809 0x9372 0x1f55 0x38d3 0x9351 0x2057 0x399d 0x932e 0x216e 0x3a67 0x9309 0x21dc 0x3b31 0x92e0 0x2307 0x3bfb 0x92d8 0x2355 0x3cc5 0x92d8 0x2355 0x3d8f 0x92d8 0x2355 0x3e59 0x92d8 0x2355 0x3f23 0x92d8 0x2355 0x3fed 0x92d8 0x2355 0x40b7 0x92d8 0x2355 0x4181 0x92d8 0x2355 0x424b 0x92d8 0x2355 0x4315 0x92d8 0x2355 0x43df 0x92d8 0x2355 0x44aa 0x92d8 0x2355 0x4574 0x92d8 0x2355 0x463e 0x92d8 0x2355 0x4708 0x92d8 0x2355 0x47d2 0x92d8 0x2355 0x489c 0x92d8 0x2355 0x4966 0x92d8 0x2355 0x4a30 0x92d8 0x2355 0x4afa 0x92d8 0x2355 0x4bc4 0x92d8 0x2355 0x4c8e 0x92d8 0x2355 0x4d58 0x92d8 0x2355 0x4e22 0x92d8 0x2355>;
				g_PMIC_MIN_VOL_row = <0x04>;
				g_PMIC_MIN_VOL_col = <0x0a>;
				g_PMIC_MIN_VOL = <0x82dc 0x82dc 0x82dc 0x82dc 0x80e8 0x80e8 0x80e8 0x80e8 0x80e8 0x80e8 0x80e8 0x80e8 0x7dc8 0x7dc8 0x7dc8 0x7dc8 0x7918 0x7918 0x7918 0x7918 0x7b0c 0x7b0c 0x7b0c 0x7b0c 0x7918 0x7918 0x7918 0x7918 0x7918 0x7918 0x7918 0x7918 0x7918 0x7918 0x7918 0x7918 0x7918 0x7918 0x7918 0x79e0>;
				g_PON_SYS_IBOOT_row = <0x04>;
				g_PON_SYS_IBOOT_col = <0x0a>;
				g_PON_SYS_IBOOT = <0x1388 0x1388 0x1388 0x1388 0x1388 0x1388 0x1388 0x1388 0x1388 0x1388 0x1388 0x1388 0x1388 0x1388 0x1388 0x1388 0x1388 0x1388 0x1388 0x1388 0x1388 0x1388 0x1388 0x1388 0x1388 0x1388 0x1388 0x1388 0x1388 0x1388 0x1388 0x1388 0x1388 0x1388 0x1388 0x1388 0x1388 0x1388 0x1388 0x1388>;
				g_QMAX_SYS_VOL_row = <0x04>;
				g_QMAX_SYS_VOL_col = <0x0a>;
				g_QMAX_SYS_VOL = <0x8886 0x8886 0x8886 0x8886 0x8886 0x8886 0x8886 0x8886 0x85ca 0x85ca 0x85ca 0x85ca 0x85ca 0x85ca 0x85ca 0x85ca 0x85ca 0x85ca 0x85ca 0x85ca 0x7ef4 0x7ef4 0x7ef4 0x7ef4 0x8020 0x8020 0x8020 0x8020 0x8020 0x8020 0x8020 0x8020 0x8020 0x8020 0x8020 0x8020 0x8020 0x8020 0x8020 0x8020>;
				g_FG_PSEUDO100_row = <0x04>;
				g_FG_PSEUDO100_col = <0x0a>;
				g_FG_PSEUDO100 = <0x64 0x64 0x64 0x64 0x64 0x64 0x64 0x64 0x64 0x64 0x64 0x64 0x64 0x64 0x64 0x64 0x64 0x64 0x64 0x64 0x64 0x64 0x64 0x64 0x64 0x64 0x64 0x64 0x64 0x64 0x64 0x64 0x64 0x64 0x64 0x64 0x64 0x64 0x64 0x64>;
				g_FG_charge_PSEUDO100_row = <0x04>;
				g_FG_charge_PSEUDO100_col = <0x0a>;
				g_FG_charge_PSEUDO100 = <0x64 0x64 0x64 0x64 0x64 0x64 0x64 0x64 0x64 0x64 0x64 0x64 0x64 0x64 0x64 0x64 0x64 0x64 0x64 0x64 0x64 0x64 0x64 0x64 0x64 0x64 0x64 0x64 0x64 0x64 0x64 0x64 0x64 0x64 0x64 0x64 0x64 0x64 0x64 0x64>;
			};

			mtk_chrdet: mtk_chrdet {
				compatible = "mediatek,mtk-chr-det";
				io-channels = <&pmic_auxadc 2>;
				io-channel-names = "pmic_vbus";
				bootmode = <&chosen>;
				bc12 = <&eta6965_chg>;
				vcdt_int_active;
			};

			mt6358_batoc_throttle: mtk_battery_oc_throttling {
				compatible = "mediatek,mt6358-battery_oc_throttling";
				oc-thd = <0x1770 0x1b58 0x1f40>;
			};
		};
	};

	pwraph: pwraphal@10026000 {
		compatible = "mediatek,pwraph";
		mediatek,pwrap-regmap = <&pwrap>;
	};

	pwrap_mpu@10026000 {
		compatible = "mediatek,pwrap_mpu";
		reg = <0x00 0x10026000 0x00 0x1000>;
	};

	vow_pmic_efuse {
		compatible = "mediatek,vow-efuse";
		nvmem = <&pmic_efuse>;
		nvmem-names = "vow_efuse_device";
		ver_reg = <0xec>;
		ver_mask = <0x1f>;
	};

};
